# f28004x_hrcap_regs register map
Vendor: Texas Instruments
Peripheral module from a debugger description file (folder C2000).
Address unit: 16 bits
Registers are 32-bit, read-write, no defined reset value unless marked. A register's access mark holds for its fields unless they carry their own. Offsets are as the file gives them; lines under a group give offsets from that group; [hi:lo] are bit positions; {n}, {i} and the like mark numbered series; 'fields as' and 'values as' point back to an identical list; <NAME> marks a mode.

## HRCAP_REGS — HRCAP Registers
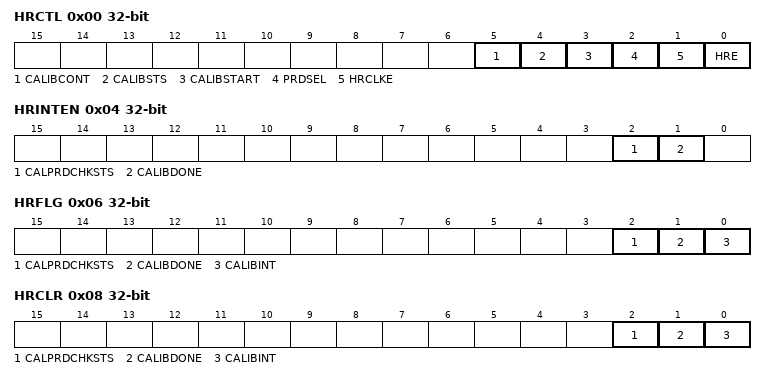
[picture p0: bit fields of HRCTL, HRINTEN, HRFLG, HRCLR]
0x00 HRCTL access not given — High-Res Control Register
  [5] CALIBCONT rw — Continuous mode Calibration Select
  [4] CALIBSTS — Calibration status (access R=0)
  [3] CALIBSTART — Calibration start (access W=1/R=0)
  [2] PRDSEL rw — Calibration Period Match
  [1] HRCLKE rw — High Resolution Clock Enable
  [0] HRE rw — High Resolution Enable
0x04 HRINTEN — High-Res Calibration Interrupt Enable Register
  [2] CALPRDCHKSTS — Calibration period check status enable
  [1] CALIBDONE — Calibration doe interrupt enable
0x06 HRFLG ro — High-Res Calibration Interrupt Flag Register
  [2] CALPRDCHKSTS — Calibration period check status Flag Bi
  [1] CALIBDONE — Calibration Done Interrupt Flag Bit
  [0] CALIBINT — Global calibration Interrupt Status Flag
0x08 HRCLR access not given — High-Res Calibration Interrupt Clear Register
  [2] CALPRDCHKSTS — Clear Calibration period check status Flag Bit: (access R=0/W=1)
  [1] CALIBDONE — Clear Calibration Done Interrupt Flag Bit (access R=0/W=1)
  [0] CALIBINT — Clear Global calibration Interrupt Flag (access R=0/W=1)
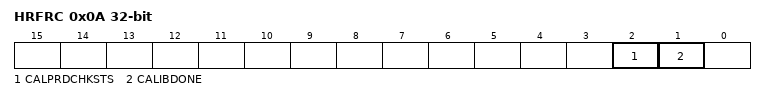
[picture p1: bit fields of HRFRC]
0x0A HRFRC access not given — High-Res Calibration Interrupt Force Register
  [2] CALPRDCHKSTS — Force Calibration period check status Flag Bit: (access R=0/W=1)
  [1] CALIBDONE — Force Calibration Done Interrupt Flag Bit (access R=0/W=1)
0x0C HRCALPRD — High-Res Calibration Period Register
  [31:0] PRD — Calibration period
0x0E HRSYSCLKCTR ro — High-Res Calibration SYSCLK Counter Register
  [31:0] HRSYSCLKCTR — Current SYCLK counter value
0x10 HRSYSCLKCAP — High-Res Calibration SYSCLK Capture Register
  [31:0] HRSYSCLKCAP — Reads captured SYSCLK counter
0x12 HRCLKCTR ro — High-Res Calibration HRCLK Counter Register
  [31:0] HRCLKCTR — Current HRCLK counter value
0x14 HRCLKCAP — High-Res Calibration HRCLK Capture Register
  [31:0] HRCLKCAP — Reads captured HRCLK counter
